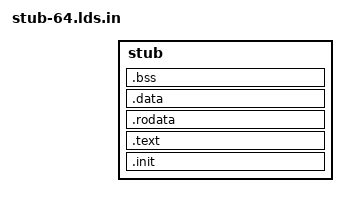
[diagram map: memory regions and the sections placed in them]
/***************************************************************************
 * Broadcom Proprietary and Confidential. (c)2016 Broadcom. All rights reserved.
 *
 *  THIS SOFTWARE MAY ONLY BE USED SUBJECT TO AN EXECUTED SOFTWARE LICENSE
 *  AGREEMENT  BETWEEN THE USER AND BROADCOM.  YOU HAVE NO RIGHT TO USE OR
 *  EXPLOIT THIS MATERIAL EXCEPT SUBJECT TO THE TERMS OF SUCH AN AGREEMENT.
 *
 ***************************************************************************/

/* stub.lds.in */

MEMORY {
	stub : ORIGIN = @STUB64_START@, LENGTH = @STUB64_SIZE@
}

ENTRY(stub_start)

SECTIONS {
	.init :
	{
		stub_start = .;
		* (.init*)
	} > stub =@FILLB@

	.text :
	{
		* (.text*)
	} > stub =@FILLB@

	.rodata :
	{
		* (.rodata)
		* (.rodata.*)
	} > stub =@FILLB@

	.data :
	{
		* (.data*)
		. = ALIGN(16);
	} > stub =@FILLB@

	.bss :
	{
		_stub_zero_start = .;
		* (.bss*)
		_stub_zero_end = .;
		. = ALIGN(4);
	} > stub =0x00
};

/* EOF */
